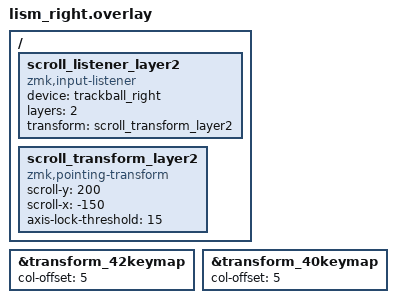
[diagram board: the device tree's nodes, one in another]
#include "lism.dtsi"

/ {
    scroll_listener_layer2: scroll_listener_layer2 {
        compatible = "zmk,input-listener";

        /* 右手トラックボール */
        device = <&trackball_right>;

        /* layer_2 の時だけ有効 */
        layers = <2>;

        transform = <&scroll_transform_layer2>;
    };

    scroll_transform_layer2: scroll_transform_layer2 {
        compatible = "zmk,pointing-transform";

        /* 縦スクロール */
        scroll-y = <200>;

        /* 横スクロール（反転） */
        scroll-x = <-150>;

        /*
         * 斜め入力を無視する設定
         * 値が大きいほど「真横／真縦」以外を切る
         */
        axis-lock-threshold = <15>;
    };
};

&transform_42keymap {
    col-offset = <5>;
};

&transform_40keymap {
    col-offset = <5>;
};
